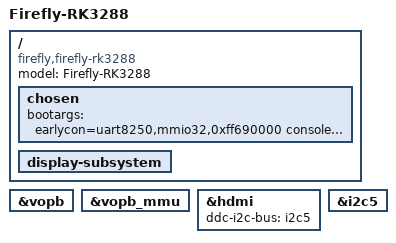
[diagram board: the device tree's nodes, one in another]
// SPDX-License-Identifier: (GPL-2.0+ OR MIT)
/*
 * Copyright (c) 2014, 2015 FUKAUMI Naoki <naobsd@gmail.com>
 */

/dts-v1/;
#include "rk3288-firefly.dtsi"

/ {
	model = "Firefly-RK3288";
	compatible = "firefly,firefly-rk3288", "rockchip,rk3288";

	chosen {
		// rootfs_in_flash
		bootargs = "earlycon=uart8250,mmio32,0xff690000 console=ttyS2,115200n8 root=PARTLABEL=new_rootfs rootfstype=squashfs rootwait init=/linuxrc ignore_loglevel";
		// rootfs_in_ramdisk
		//bootargs = "earlycon=uart8250,mmio32,0xff690000 console=ttyS2,115200n8 root=/dev/ram initrd=0x04000000,0x00c00000 ramdisk_size=12288 rdinit=/linuxrc init=/linuxrc ignore_loglevel";
	};

	display-subsystem {
		status = "okay";
	};
};

&vopb {
	status = "okay";
};

&vopb_mmu {
	status = "okay";
};

&hdmi {
	ddc-i2c-bus = <&i2c5>;
	status = "okay";
};

&i2c5 {
	status = "okay";
};
